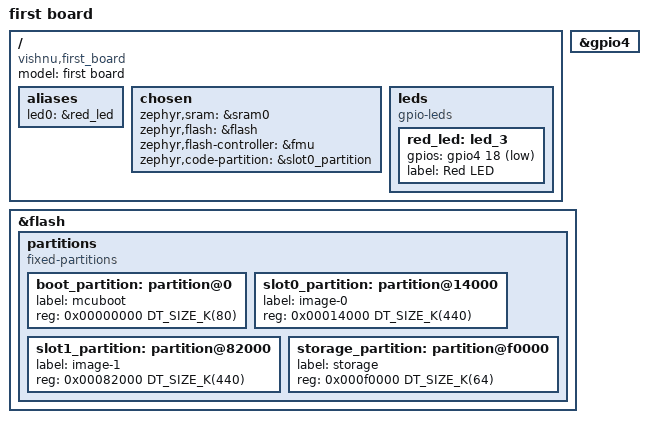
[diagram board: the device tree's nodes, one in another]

/dts-v1/;

#include <nxp/mcx/mcxn/nxp_mcxn23x.dtsi>

/ {
	model = "first board";
	compatible = "vishnu,first_board";

	aliases {
		led0 = &red_led;
	};

	chosen {
		zephyr,sram = &sram0;
		zephyr,flash = &flash;
		zephyr,flash-controller = &fmu;
		zephyr,code-partition = &slot0_partition;
	};

	leds {
		compatible = "gpio-leds";

		red_led: led_3 {
			gpios = <&gpio4 18 GPIO_ACTIVE_LOW>;
			label = "Red LED";
		};
	};
};

&gpio4 {
	status = "okay";
};

&flash {
	partitions {
		compatible = "fixed-partitions";
		#address-cells = <1>;
		#size-cells = <1>;

		boot_partition: partition@0 {
			label = "mcuboot";
			reg = <0x00000000 DT_SIZE_K(80)>;
		};

		slot0_partition: partition@14000 {
			label = "image-0";
			reg = <0x00014000 DT_SIZE_K(440)>;
		};

		slot1_partition: partition@82000 {
			label = "image-1";
			reg = <0x00082000 DT_SIZE_K(440)>;
		};

		storage_partition: partition@f0000 {
			label = "storage";
			reg = <0x000f0000 DT_SIZE_K(64)>;
		};
	};
};
